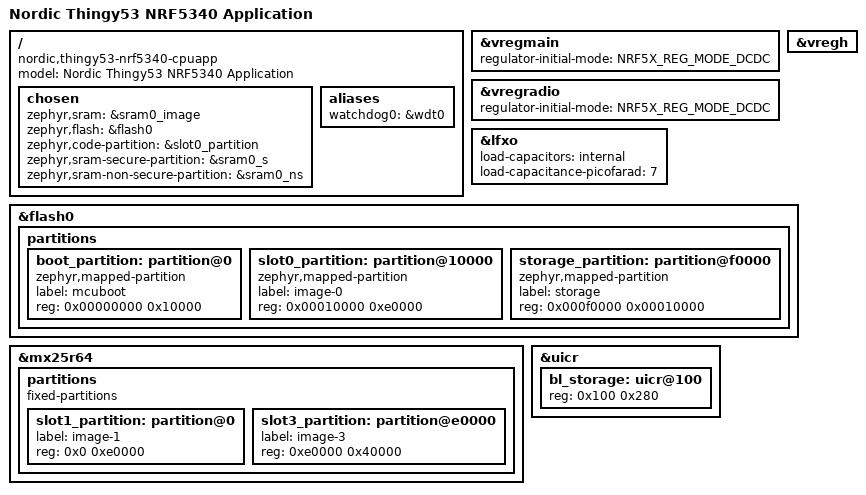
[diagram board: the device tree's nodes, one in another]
/*
 * Copyright (c) 2021 Nordic Semiconductor ASA
 *
 * SPDX-License-Identifier: Apache-2.0
 */

/dts-v1/;
#include <nordic/nrf5340_cpuapp_qkaa.dtsi>
#include "thingy53_nrf5340_common.dtsi"
#include <../boards/common/usb/cdc_acm_serial.dtsi>

/ {
	model = "Nordic Thingy53 NRF5340 Application";
	compatible = "nordic,thingy53-nrf5340-cpuapp";

	chosen {
		zephyr,sram = &sram0_image;
		zephyr,flash = &flash0;
		zephyr,code-partition = &slot0_partition;
		zephyr,sram-secure-partition = &sram0_s;
		zephyr,sram-non-secure-partition = &sram0_ns;
	};

	aliases {
		watchdog0 = &wdt0;
	};
};

&vregmain {
	regulator-initial-mode = <NRF5X_REG_MODE_DCDC>;
};

&vregradio {
	regulator-initial-mode = <NRF5X_REG_MODE_DCDC>;
};

&vregh {
	status = "okay";
};

&lfxo {
	load-capacitors = "internal";
	load-capacitance-picofarad = <7>;
};

&flash0 {
	partitions {
		ranges;
		#address-cells = <1>;
		#size-cells = <1>;

		boot_partition: partition@0 {
			compatible = "zephyr,mapped-partition";
			label = "mcuboot";
			reg = <0x00000000 0x10000>;
		};

		slot0_partition: partition@10000 {
			compatible = "zephyr,mapped-partition";
			label = "image-0";
			reg = <0x00010000 0xe0000>;
		};

		storage_partition: partition@f0000 {
			compatible = "zephyr,mapped-partition";
			label = "storage";
			reg = <0x000f0000 0x00010000>;
		};
	};
};


&mx25r64 {
	partitions {
		compatible = "fixed-partitions";
		#address-cells = <1>;
		#size-cells = <1>;

		slot1_partition: partition@0 {
			label = "image-1";
			reg = <0x0 0xe0000>;
		};

		slot3_partition: partition@e0000 {
			label = "image-3";
			reg = <0xe0000 0x40000>;
		};
	};
};

&uicr {
	bl_storage: uicr@100 {
		reg = <0x100 0x280>;
	};
};

#include "nordic/nrf5340_sram_partition.dtsi"
#include "nordic/nrf5340_shared_sram_partition.dtsi"
